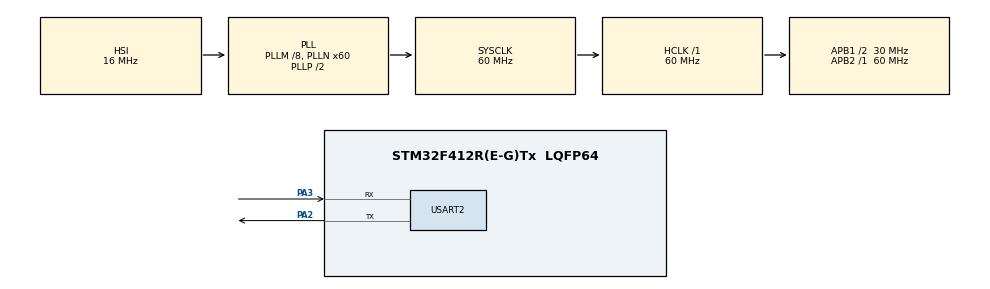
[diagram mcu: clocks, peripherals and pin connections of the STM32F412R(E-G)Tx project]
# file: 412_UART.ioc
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Mcu.Family=STM32F4
Mcu.Name=STM32F412R(E-G)Tx
Mcu.Package=LQFP64
NVIC.PriorityGroup=NVIC_PRIORITYGROUP_4
PA13.Mode=Serial_Wire
PA13.Signal=SYS_JTMS-SWDIO
PA14.Mode=Serial_Wire
PA14.Signal=SYS_JTCK-SWCLK
PA2.Mode=Asynchronous
PA2.Signal=USART2_TX
PA3.Mode=Asynchronous
PA3.Signal=USART2_RX
ProjectManager.HeapSize=0x200
ProjectManager.StackSize=0x400
ProjectManager.TargetToolchain=STM32CubeIDE
RCC.AHBFreq_Value=60000000
RCC.APB1CLKDivider=RCC_HCLK_DIV2
RCC.APB1Freq_Value=30000000
RCC.APB1TimFreq_Value=60000000
RCC.APB2Freq_Value=60000000
RCC.APB2TimFreq_Value=60000000
RCC.CortexFreq_Value=60000000
RCC.HCLKFreq_Value=60000000
RCC.HSE_VALUE=8000000
RCC.PLLM=8
RCC.PLLN=60
RCC.SYSCLKFreq_VALUE=60000000
RCC.SYSCLKSource=RCC_SYSCLKSOURCE_PLLCLK
RCC.USBFreq_Value=60000000
RCC.VCOOutputFreq_Value=120000000
USART2.VirtualMode=VM_ASYNC
board=custom

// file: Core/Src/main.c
/* USER CODE BEGIN Header */
/**
  ******************************************************************************
  * @file           : main.c
  * @brief          : UART2 Test – Prints "Hello\r\n" every 500ms
  ******************************************************************************
  */
/* USER CODE END Header */
#include "main.h"

/* USER CODE BEGIN Includes */
#include "string.h"
#include "stdio.h"
/* USER CODE END Includes */

UART_HandleTypeDef huart2;

/* USER CODE BEGIN PV */
char msg[] = "Hello\r\n";
/* USER CODE END PV */

void SystemClock_Config(void);
static void MX_GPIO_Init(void);
static void MX_USART2_UART_Init(void);

int main(void)
{

  /* MCU Configuration--------------------------------------------------------*/

  /* Reset of all peripherals, Initializes the Flash interface and the Systick. */
  HAL_Init();

  /* Configure the system clock */
  SystemClock_Config();

  /* Initialize all configured peripherals */
  MX_GPIO_Init();
  MX_USART2_UART_Init();

  /* Infinite loop */
  while (1)
  {

    /* USER CODE BEGIN 3 */
	  HAL_UART_Transmit(&huart2, (uint8_t *)msg, strlen(msg), HAL_MAX_DELAY);
	  HAL_Delay(500);

  }
  /* USER CODE END 3 */
}

void SystemClock_Config(void)
{
  RCC_OscInitTypeDef RCC_OscInitStruct = {0};
  RCC_ClkInitTypeDef RCC_ClkInitStruct = {0};

  /** Configure the main internal regulator output voltage
  */
  __HAL_RCC_PWR_CLK_ENABLE();
  __HAL_PWR_VOLTAGESCALING_CONFIG(PWR_REGULATOR_VOLTAGE_SCALE1);

  /** Initializes the RCC Oscillators according to the specified parameters
  * in the RCC_OscInitTypeDef structure.
  */
  RCC_OscInitStruct.OscillatorType = RCC_OSCILLATORTYPE_HSI;
  RCC_OscInitStruct.HSIState = RCC_HSI_ON;
  RCC_OscInitStruct.HSICalibrationValue = RCC_HSICALIBRATION_DEFAULT;
  RCC_OscInitStruct.PLL.PLLState = RCC_PLL_ON;
  RCC_OscInitStruct.PLL.PLLSource = RCC_PLLSOURCE_HSI;
  RCC_OscInitStruct.PLL.PLLM = 8;
  RCC_OscInitStruct.PLL.PLLN = 60;
  RCC_OscInitStruct.PLL.PLLP = RCC_PLLP_DIV2;
  RCC_OscInitStruct.PLL.PLLQ = 2;
  RCC_OscInitStruct.PLL.PLLR = 2;
  if (HAL_RCC_OscConfig(&RCC_OscInitStruct) != HAL_OK)
  {
    Error_Handler();
  }

  /** Initializes the CPU, AHB and APB buses clocks
  */
  RCC_ClkInitStruct.ClockType = RCC_CLOCKTYPE_HCLK|RCC_CLOCKTYPE_SYSCLK
                              |RCC_CLOCKTYPE_PCLK1|RCC_CLOCKTYPE_PCLK2;
  RCC_ClkInitStruct.SYSCLKSource = RCC_SYSCLKSOURCE_PLLCLK;
  RCC_ClkInitStruct.AHBCLKDivider = RCC_SYSCLK_DIV1;
  RCC_ClkInitStruct.APB1CLKDivider = RCC_HCLK_DIV2;
  RCC_ClkInitStruct.APB2CLKDivider = RCC_HCLK_DIV1;

  if (HAL_RCC_ClockConfig(&RCC_ClkInitStruct, FLASH_LATENCY_1) != HAL_OK)
  {
    Error_Handler();
  }
}

static void MX_USART2_UART_Init(void)
{

  huart2.Instance = USART2;
  huart2.Init.BaudRate = 115200;
  huart2.Init.WordLength = UART_WORDLENGTH_8B;
  huart2.Init.StopBits = UART_STOPBITS_1;
  huart2.Init.Parity = UART_PARITY_NONE;
  huart2.Init.Mode = UART_MODE_TX_RX;
  huart2.Init.HwFlowCtl = UART_HWCONTROL_NONE;
  huart2.Init.OverSampling = UART_OVERSAMPLING_16;
  if (HAL_UART_Init(&huart2) != HAL_OK)
  {
    Error_Handler();
  }

}

static void MX_GPIO_Init(void)
{

  /* GPIO Ports Clock Enable */
  __HAL_RCC_GPIOA_CLK_ENABLE();

}

void Error_Handler(void)
{
  __disable_irq();
  while (1)
  {
  }
}
